VERSION "Thermistor Test DBC"

NS_ :

BS_:

BU_: BMS

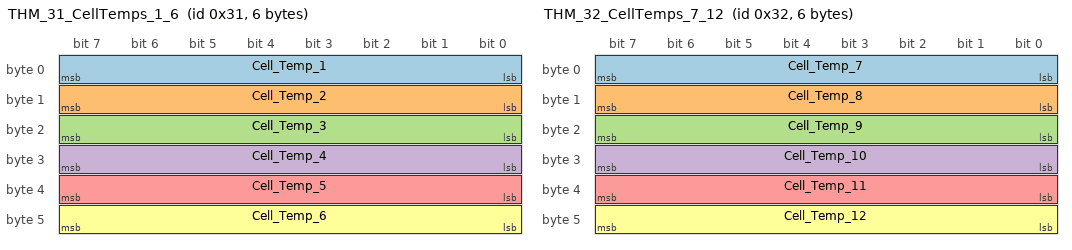
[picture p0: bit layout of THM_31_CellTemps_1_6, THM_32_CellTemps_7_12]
BO_ 49 THM_31_CellTemps_1_6: 6 BMS
 SG_ Cell_Temp_1  : 0|8@1+ (1,0) [0|255] "degC" Vector__XXX
 SG_ Cell_Temp_2  : 8|8@1+ (1,0) [0|255] "degC" Vector__XXX
 SG_ Cell_Temp_3  : 16|8@1+ (1,0) [0|255] "degC" Vector__XXX
 SG_ Cell_Temp_4  : 24|8@1+ (1,0) [0|255] "degC" Vector__XXX
 SG_ Cell_Temp_5  : 32|8@1+ (1,0) [0|255] "degC" Vector__XXX
 SG_ Cell_Temp_6  : 40|8@1+ (1,0) [0|255] "degC" Vector__XXX

BO_ 50 THM_32_CellTemps_7_12: 6 BMS
 SG_ Cell_Temp_7  : 0|8@1+ (1,0) [0|255] "degC" Vector__XXX
 SG_ Cell_Temp_8  : 8|8@1+ (1,0) [0|255] "degC" Vector__XXX
 SG_ Cell_Temp_9  : 16|8@1+ (1,0) [0|255] "degC" Vector__XXX
 SG_ Cell_Temp_10 : 24|8@1+ (1,0) [0|255] "degC" Vector__XXX
 SG_ Cell_Temp_11 : 32|8@1+ (1,0) [0|255] "degC" Vector__XXX
 SG_ Cell_Temp_12 : 40|8@1+ (1,0) [0|255] "degC" Vector__XXX

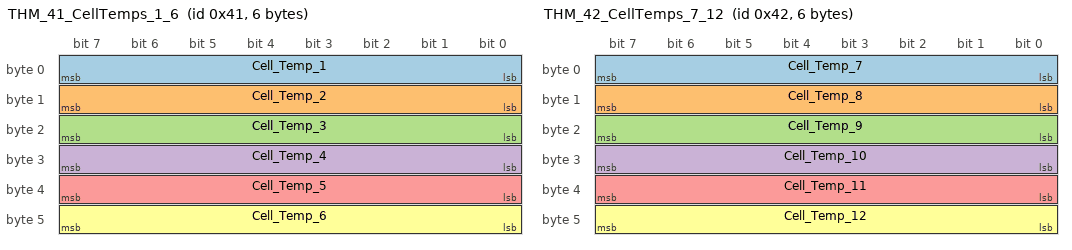
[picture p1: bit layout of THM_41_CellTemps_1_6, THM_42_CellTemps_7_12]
BO_ 65 THM_41_CellTemps_1_6: 6 BMS
 SG_ Cell_Temp_1  : 0|8@1+ (1,0) [0|255] "degC" Vector__XXX
 SG_ Cell_Temp_2  : 8|8@1+ (1,0) [0|255] "degC" Vector__XXX
 SG_ Cell_Temp_3  : 16|8@1+ (1,0) [0|255] "degC" Vector__XXX
 SG_ Cell_Temp_4  : 24|8@1+ (1,0) [0|255] "degC" Vector__XXX
 SG_ Cell_Temp_5  : 32|8@1+ (1,0) [0|255] "degC" Vector__XXX
 SG_ Cell_Temp_6  : 40|8@1+ (1,0) [0|255] "degC" Vector__XXX

BO_ 66 THM_42_CellTemps_7_12: 6 BMS
 SG_ Cell_Temp_7  : 0|8@1+ (1,0) [0|255] "degC" Vector__XXX
 SG_ Cell_Temp_8  : 8|8@1+ (1,0) [0|255] "degC" Vector__XXX
 SG_ Cell_Temp_9  : 16|8@1+ (1,0) [0|255] "degC" Vector__XXX
 SG_ Cell_Temp_10 : 24|8@1+ (1,0) [0|255] "degC" Vector__XXX
 SG_ Cell_Temp_11 : 32|8@1+ (1,0) [0|255] "degC" Vector__XXX
 SG_ Cell_Temp_12 : 40|8@1+ (1,0) [0|255] "degC" Vector__XXX

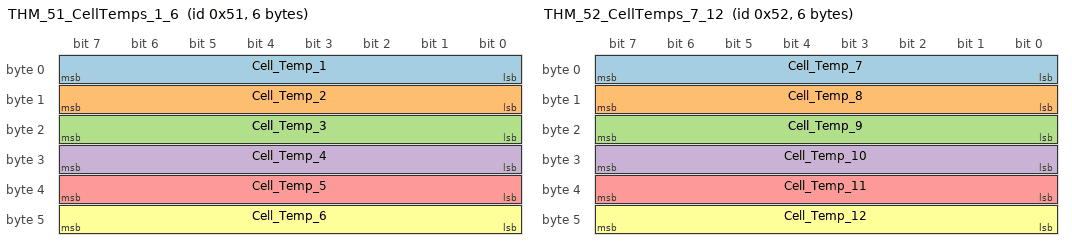
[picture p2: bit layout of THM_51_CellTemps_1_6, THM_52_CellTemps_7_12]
BO_ 81 THM_51_CellTemps_1_6: 6 BMS
 SG_ Cell_Temp_1  : 0|8@1+ (1,0) [0|255] "degC" Vector__XXX
 SG_ Cell_Temp_2  : 8|8@1+ (1,0) [0|255] "degC" Vector__XXX
 SG_ Cell_Temp_3  : 16|8@1+ (1,0) [0|255] "degC" Vector__XXX
 SG_ Cell_Temp_4  : 24|8@1+ (1,0) [0|255] "degC" Vector__XXX
 SG_ Cell_Temp_5  : 32|8@1+ (1,0) [0|255] "degC" Vector__XXX
 SG_ Cell_Temp_6  : 40|8@1+ (1,0) [0|255] "degC" Vector__XXX

BO_ 82 THM_52_CellTemps_7_12: 6 BMS
 SG_ Cell_Temp_7  : 0|8@1+ (1,0) [0|255] "degC" Vector__XXX
 SG_ Cell_Temp_8  : 8|8@1+ (1,0) [0|255] "degC" Vector__XXX
 SG_ Cell_Temp_9  : 16|8@1+ (1,0) [0|255] "degC" Vector__XXX
 SG_ Cell_Temp_10 : 24|8@1+ (1,0) [0|255] "degC" Vector__XXX
 SG_ Cell_Temp_11 : 32|8@1+ (1,0) [0|255] "degC" Vector__XXX
 SG_ Cell_Temp_12 : 40|8@1+ (1,0) [0|255] "degC" Vector__XXX

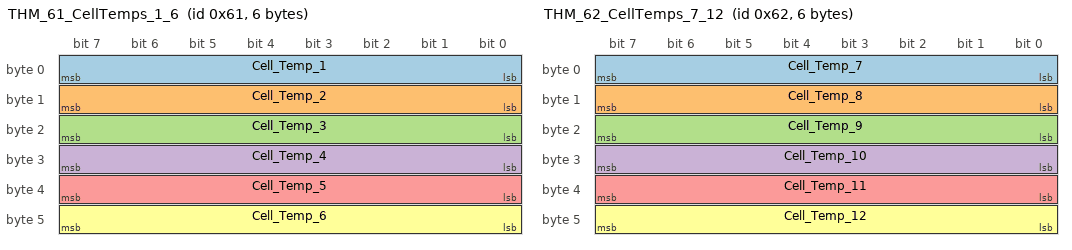
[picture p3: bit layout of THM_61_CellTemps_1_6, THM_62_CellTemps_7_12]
BO_ 97 THM_61_CellTemps_1_6: 6 BMS
 SG_ Cell_Temp_1  : 0|8@1+ (1,0) [0|255] "degC" Vector__XXX
 SG_ Cell_Temp_2  : 8|8@1+ (1,0) [0|255] "degC" Vector__XXX
 SG_ Cell_Temp_3  : 16|8@1+ (1,0) [0|255] "degC" Vector__XXX
 SG_ Cell_Temp_4  : 24|8@1+ (1,0) [0|255] "degC" Vector__XXX
 SG_ Cell_Temp_5  : 32|8@1+ (1,0) [0|255] "degC" Vector__XXX
 SG_ Cell_Temp_6  : 40|8@1+ (1,0) [0|255] "degC" Vector__XXX

BO_ 98 THM_62_CellTemps_7_12: 6 BMS
 SG_ Cell_Temp_7  : 0|8@1+ (1,0) [0|255] "degC" Vector__XXX
 SG_ Cell_Temp_8  : 8|8@1+ (1,0) [0|255] "degC" Vector__XXX
 SG_ Cell_Temp_9  : 16|8@1+ (1,0) [0|255] "degC" Vector__XXX
 SG_ Cell_Temp_10 : 24|8@1+ (1,0) [0|255] "degC" Vector__XXX
 SG_ Cell_Temp_11 : 32|8@1+ (1,0) [0|255] "degC" Vector__XXX
 SG_ Cell_Temp_12 : 40|8@1+ (1,0) [0|255] "degC" Vector__XXX
